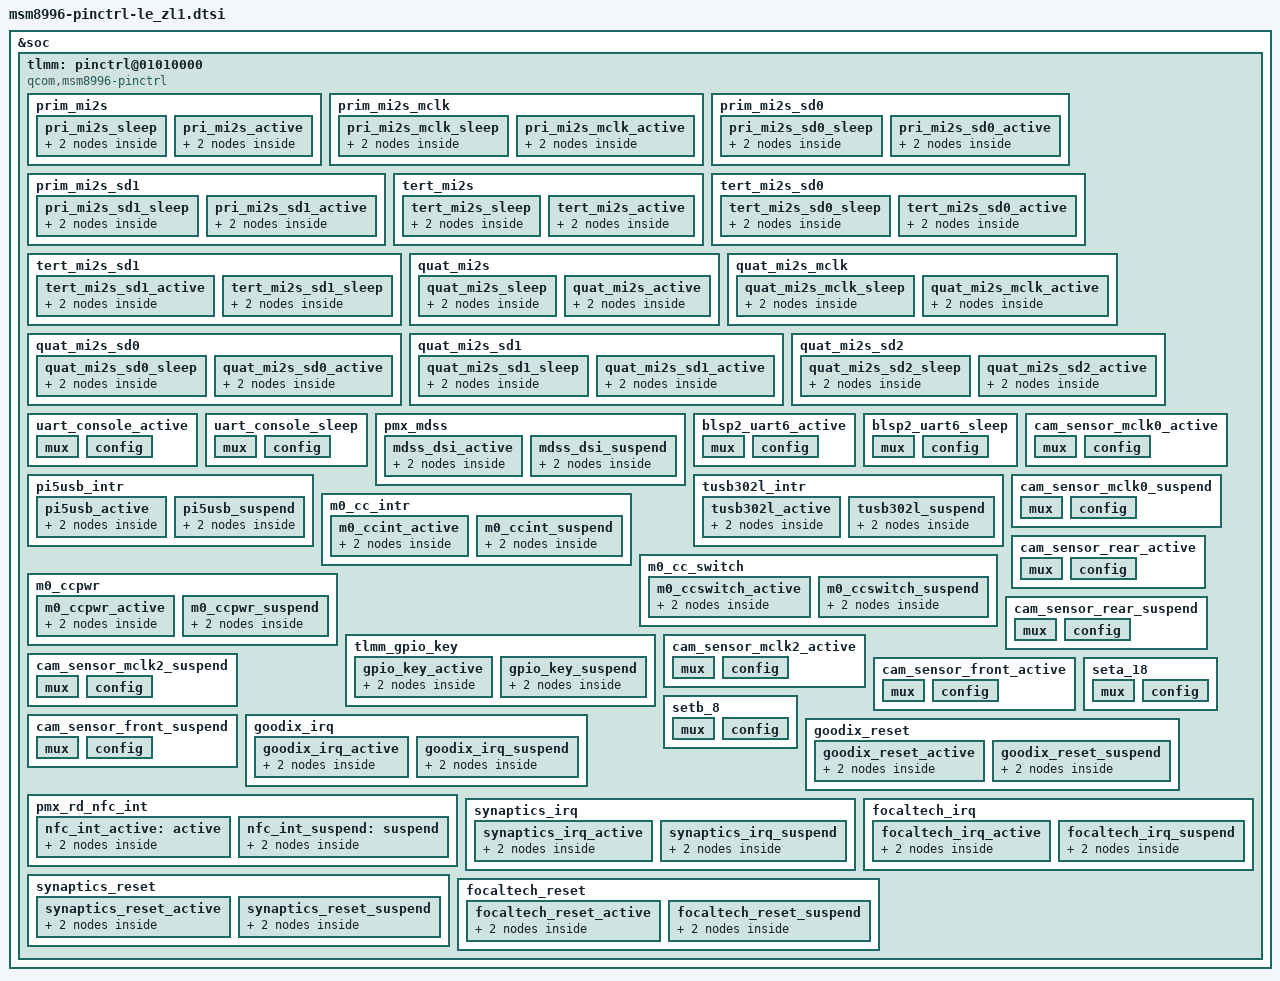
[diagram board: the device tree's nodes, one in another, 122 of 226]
/* Copyright (c) 2014-2015, The Linux Foundation. All rights reserved.
 *
 * This program is free software; you can redistribute it and/or modify
 * it under the terms of the GNU General Public License version 2 and
 * only version 2 as published by the Free Software Foundation.
 *
 * This program is distributed in the hope that it will be useful,
 * but WITHOUT ANY WARRANTY; without even the implied warranty of
 * MERCHANTABILITY or FITNESS FOR A PARTICULAR PURPOSE.  See the
 * GNU General Public License for more details.
 */

&soc {
	tlmm: pinctrl@01010000 {
		compatible = "qcom,msm8996-pinctrl";
		reg = <0x01010000 0x300000>;
		interrupts = <0 208 0>;
		gpio-controller;
		#gpio-cells = <2>;
		interrupt-controller;
		#interrupt-cells = <2>;

/*********** audio MI2S gpio config start ***********/
		prim_mi2s {
			pri_mi2s_sleep: pri_mi2s_sleep {
				mux {
					pins = "gpio65", "gpio66";
					function = "pri_mi2s";
				};
				config {
					pins = "gpio65", "gpio66";
					drive-strength = <2>;   /* 2 mA */
					bias-pull-down;         /* PULL DOWN */
				};
			};
			pri_mi2s_active: pri_mi2s_active {
				mux {
					pins = "gpio65", "gpio66";
					function = "pri_mi2s";
				};
				config {
					pins = "gpio65", "gpio66";
					drive-strength = <8>;   /* 8 mA */
					bias-disable;           /* NO PULL */
					output-high;
				};
			};
		};

		prim_mi2s_mclk {
			pri_mi2s_mclk_sleep: pri_mi2s_mclk_sleep {
				mux {
					pins = "gpio64";
					function = "pri_mi2s";
				};
				config {
					pins = "gpio64";
					drive-strength = <2>;   /* 2 mA */
					bias-pull-down;         /* PULL DOWN */
				};
			};
			pri_mi2s_mclk_active: pri_mi2s_mclk_active {
				mux {
					pins = "gpio64";
					function = "pri_mi2s";
				};
				config {
					pins = "gpio64";
					drive-strength = <8>;   /* 8 mA */
					bias-disable;           /* NO PULL */
					output-high;
				};
			};
		};

		prim_mi2s_sd0 {
			pri_mi2s_sd0_sleep: pri_mi2s_sd0_sleep {
				mux {
					pins = "gpio67";
					function = "pri_mi2s";
				};
				config {
					pins = "gpio67";
					drive-strength = <2>;   /* 2 mA */
					bias-pull-down;         /* PULL DOWN */
				};
			};
			pri_mi2s_sd0_active: pri_mi2s_sd0_active {
				mux {
					pins = "gpio67";
					function = "pri_mi2s";
				};
				config {
					pins = "gpio67";
					drive-strength = <8>;   /* 8 mA */
					bias-disable;           /* NO PULL */
				};
			};
		};

		prim_mi2s_sd1 {
			pri_mi2s_sd1_sleep: pri_mi2s_sd1_sleep {
				mux {
					pins = "gpio68";
					function = "pri_mi2s";
				};
				config {
					pins = "gpio68";
					drive-strength = <2>;   /* 2 mA */
					bias-pull-down;         /* PULL DOWN */
				};
			};
			pri_mi2s_sd1_active: pri_mi2s_sd1_active {
				mux {
					pins = "gpio68";
					function = "pri_mi2s";
				};
				config {
					pins = "gpio68";
					drive-strength = <8>;   /* 8 mA */
					bias-disable;           /* NO PULL */
				};
			};
		};

		tert_mi2s {
			tert_mi2s_sleep: tert_mi2s_sleep {
				mux {
					pins = "gpio75", "gpio76";
					function = "ter_mi2s";
				};

				config {
					pins = "gpio75", "gpio76";
					drive-strength = <2>;   /* 2 mA */
					bias-pull-down;         /* PULL DOWN */
				};
			};
			tert_mi2s_active: tert_mi2s_active {
				mux {
					pins = "gpio75", "gpio76";
					function = "ter_mi2s";
				};

				config {
					pins = "gpio75", "gpio76";
					drive-strength = <8>;   /* 8 mA */
					bias-disable;           /* NO PULL */
					output-high;
				};
			};
		};

		tert_mi2s_sd0 {
			tert_mi2s_sd0_sleep: tert_mi2s_sd0_sleep {
				mux {
					pins = "gpio77";
					function = "ter_mi2s";
				};

				config {
					pins = "gpio77";
					drive-strength = <2>;   /* 2 mA */
					bias-pull-down;         /* PULL DOWN */
				};
			};
			tert_mi2s_sd0_active: tert_mi2s_sd0_active {
				mux {
					pins = "gpio77";
					function = "ter_mi2s";
				};

				config {
					pins = "gpio77";
					drive-strength = <8>;   /* 8 mA */
					bias-disable;           /* NO PULL */
				};
			};
		};

		tert_mi2s_sd1 {
			tert_mi2s_sd1_active: tert_mi2s_sd1_active {
				mux {
					pins = "gpio78";
					function = "ter_mi2s";
				};

				config {
					pins = "gpio78";
					drive-strength = <8>;   /* 8 mA */
					bias-disable;           /* NO PULL */
				};
			};

			tert_mi2s_sd1_sleep: tert_mi2s_sd1_sleep {
				mux {
					pins = "gpio78";
					function = "ter_mi2s";
				};

				config {
					pins = "gpio78";
					drive-strength = <2>;   /* 2 mA */
					bias-pull-down;         /* PULL DOWN */
				};
			};
		};

		quat_mi2s {
			quat_mi2s_sleep: quat_mi2s_sleep {
				mux {
					pins = "gpio58", "gpio59";
					function = "qua_mi2s";
				};

				config {
					pins = "gpio58", "gpio59";
					drive-strength = <2>;   /* 2 mA */
					bias-pull-down;         /* PULL DOWN */
				};
			};
			quat_mi2s_active: quat_mi2s_active {
				mux {
					pins = "gpio58", "gpio59";
					function = "qua_mi2s";
				};

				config {
					pins = "gpio58", "gpio59";
					drive-strength = <8>;   /* 8 mA */
					bias-disable;           /* NO PULL */
					output-high;
				};
			};
		};

		quat_mi2s_mclk {
			quat_mi2s_mclk_sleep: quat_mi2s_mclk_sleep {
				mux {
					pins = "gpio57";
					function = "qua_mi2s";
				};
				config {
					pins = "gpio57";
					drive-strength = <2>;   /* 2 mA */
					bias-pull-down;         /* PULL DOWN */
				};
			};
			quat_mi2s_mclk_active: quat_mi2s_mclk_active {
				mux {
					pins = "gpio57";
					function = "qua_mi2s";
				};
				config {
					pins = "gpio57";
					drive-strength = <8>;   /* 8 mA */
					bias-disable;           /* NO PULL */
					output-high;
				};
			};
		};

		quat_mi2s_sd0 {
			quat_mi2s_sd0_sleep: quat_mi2s_sd0_sleep {
				mux {
					pins = "gpio60";
					function = "qua_mi2s";
				};

				config {
					pins = "gpio60";
					drive-strength = <2>;   /* 2 mA */
					bias-pull-down;         /* PULL DOWN */
				};
			};
			quat_mi2s_sd0_active: quat_mi2s_sd0_active {
				mux {
					pins = "gpio60";
					function = "qua_mi2s";
				};

				config {
					pins = "gpio60";
					drive-strength = <8>;   /* 8 mA */
					bias-disable;           /* NO PULL */
				};
			};
		};

		quat_mi2s_sd1 {
			quat_mi2s_sd1_sleep: quat_mi2s_sd1_sleep {
				mux {
					pins = "gpio61";
					function = "qua_mi2s";
				};
				config {
					pins = "gpio61";
					drive-strength = <2>;   /* 2 mA */
					bias-pull-down;         /* PULL DOWN */
				};
			};
			quat_mi2s_sd1_active: quat_mi2s_sd1_active {
				mux {
					pins = "gpio61";
					function = "qua_mi2s";
				};
				config {
					pins = "gpio61";
					function = "qua_mi2s";
					drive-strength = <8>;   /* 8 mA */
					bias-disable;           /* NO PULL */
				};
			};
		};

		quat_mi2s_sd2 {
			quat_mi2s_sd2_sleep: quat_mi2s_sd2_sleep {
				mux {
					pins = "gpio62";
					function = "qua_mi2s";
				};
				config {
					pins = "gpio62";
					drive-strength = <2>;   /* 2 mA */
					bias-pull-down;         /* PULL DOWN */
				};
			};
			quat_mi2s_sd2_active: quat_mi2s_sd2_active {
				mux {
					pins = "gpio62";
					function = "qua_mi2s";
				};
				config {
					pins = "gpio62";
					drive-strength = <8>;   /* 8 mA */
					bias-disable;           /* NO PULL */
				};
			};
		};
/*********** audio MI2S gpio config end ***********/

/*********** UART gpio config start ***********/
		uart_console_active: uart_console_active {
			mux {
				pins = "gpio4", "gpio5";
				function = "blsp_uart8";
			};

			config {
				pins = "gpio4", "gpio5";
				drive-strength = <6>;
				bias-disable;
			};
		};

		uart_console_sleep: uart_console_sleep {
			mux {
				pins = "gpio4", "gpio5";
				function = "gpio";
			};

			config {
				pins = "gpio4", "gpio5";
				drive-strength = <6>;
				bias-pull-down;
				output-low;
			};
		};
/*********** UART gpio config end ***********/

/*********** lcd gpio config start ***********/
		pmx_mdss: pmx_mdss {
			mdss_dsi_active: mdss_dsi_active {
				mux {
					pins = "gpio24";
					function = "gpio";
				};

				pmx_mdss {
					pins = "gpio24";
					drive-strength = <8>; /* 8 mA */
					bias-disable = <0>; /* no pull */
					output-high;
				};
			};
			mdss_dsi_suspend: mdss_dsi_suspend {
				mux {
					pins = "gpio24";
					function = "gpio";
				};

				config {
					pins = "gpio24";
					drive-strength = <2>; /* 2 mA */
					bias-pull-down;	/* pull	down */
				};
			};
		};
/*********** lcd gpio config end ***********/

/*********** IR MAXQ616 config start ***********/
	blsp2_uart6_active: blsp2_uart6_active {
		mux {
			pins = "gpio85", "gpio86";
			function = "blsp_uart12";
		};

		config {
			pins = "gpio85", "gpio86";
			drive-strength = <2>;
			bias-disable = <0>;
		};
	};

	blsp2_uart6_sleep: blsp2_uart6_sleep {
		mux {
			pins = "gpio85", "gpio86";
			function = "gpio";
		};

		config {
			pins = "gpio85", "gpio86";
			drive-strength = <2>;
			bias_disable = <0>;
			output-low;
		};
	};
/*********** IR MAXQ616 config end ***********/

/*********** usb cc logic gpio config start ***********/
		pi5usb_intr {
			pi5usb_active: pi5usb_active {
				mux {
					pins = "gpio73";
					function = "gpio";
				};

				config {
					pins = "gpio73";
					drive-strength = <2>;
					 bias-pull-up;
				};
			};
			pi5usb_suspend: pi5usb_suspend {
				mux {
					pins = "gpio73";
					function = "gpio";
				};

				config {
					pins = "gpio73";
					drive-strength = <2>;
					 bias-pull-up;
				};
			};
		};

		tusb302l_intr {
			tusb302l_active: tusb302l_active {
				mux {
					pins = "gpio73";
					function = "gpio";
				};

				config {
					pins = "gpio73";
					drive-strength = <2>;
					bias-pull-up;
				};
			};
			tusb302l_suspend: tusb302l_suspend {
				mux {
					pins = "gpio73";
					function = "gpio";
				};

				config {
					pins = "gpio73";
					drive-strength = <2>;
					bias-pull-up;
				};
			};
		};

		m0_cc_intr {
			m0_ccint_active: m0_ccint_active {
				mux {
					pins = "gpio73";
					function = "gpio";
				};

				config {
					pins = "gpio73";
					drive-strength = <2>;
					bias-pull-up;
				};
			};
			m0_ccint_suspend: m0_ccint_suspend {
				mux {
					pins = "gpio73";
					function = "gpio";
				};

				config {
					pins = "gpio73";
					drive-strength = <2>;
					bias-pull-up;
				};
			};
		};

		m0_cc_switch {
			m0_ccswitch_active: m0_ccswitch_active {
				mux {
					pins = "gpio58", "gpio59";
					function = "gpio";
				};

				config {
					pins = "gpio58", "gpio59";
					drive-strength = <2>;
					bias-pull-down;
				};
			};
			m0_ccswitch_suspend: m0_ccswitch_suspend {
				mux {
					pins = "gpio58", "gpio59";
					function = "gpio";
				};

				config {
					pins = "gpio58", "gpio59";
					drive-strength = <2>;
					bias-pull-down;
				};
			};
		};

		m0_ccpwr {
			m0_ccpwr_active: m0_ccpwr_active {
				mux {
					pins = "gpio60", "gpio61";
					function = "gpio";
				};

				config {
					pins = "gpio60", "gpio61";
					drive-strength = <2>;
					bias-pull-down;
				};
			};
			m0_ccpwr_suspend: m0_ccpwr_suspend {
				mux {
					pins = "gpio60", "gpio61";
					function = "gpio";
				};

				config {
					pins = "gpio60", "gpio61";
					drive-strength = <2>;
					bias-pull-down;
				};
			};
		};
/*********** usb cc logic gpio config end ***********/

/*********** touch key gpio config start ***********/
		tlmm_gpio_key{
			gpio_key_active: gpio_key_active {
				mux {
					pins = "gpio126";
					function = "gpio";
				};
				config {
					pins = "gpio126";
					drive-strength = <2>;
					bias-pull-up;
				};
			};
			gpio_key_suspend: gpio_key_suspend {
				mux {
					pins = "gpio126";
					function = "gpio";
				};
				config {
					pins = "gpio126";
					drive-strength = <2>;
					bias-pull-up;
				};
			};
		};
/*********** touch key gpio config end ***********/

/*********** Rear/Front Camera config start ***********/
		cam_sensor_mclk0_active: cam_sensor_mclk0_active {
			/* MCLK0 */
			mux {
				/* CLK, DATA */
				pins = "gpio13";
				function = "cam_mclk";
			};

			config {
				pins = "gpio13";
				bias-disable; /* No PULL */
				drive-strength = <2>; /* 2 MA */
			};
		};

		cam_sensor_mclk0_suspend: cam_sensor_mclk0_suspend {
			/* MCLK0 */
			mux {
				/* CLK, DATA */
				pins = "gpio13";
				function = "cam_mclk";
			};

			config {
				pins = "gpio13";
				bias-pull-down; /* PULL DOWN */
				drive-strength = <2>; /* 2 MA */
			};
		};

		cam_sensor_rear_active: cam_sensor_rear_active {
			/* RESET */
			mux {
				pins = "gpio29";
				function = "gpio";
			};

			config {
				pins = "gpio29";
				bias-disable; /* No PULL */
				drive-strength = <2>; /* 2 MA */
			};
		};

		cam_sensor_rear_suspend: cam_sensor_rear_suspend{
			/* RESET */
			mux {
				pins = "gpio29";
				function = "gpio";
			};

			config {
				pins = "gpio29";
				bias-disable; /* No PULL */
				drive-strength = <2>; /* 2 MA */
			};
		};

		cam_sensor_mclk2_active: cam_sensor_mclk2_active {
			/* MCLK1 */
			mux {
				/* CLK, DATA */
				pins = "gpio15";
				function = "cam_mclk";
			};

			config {
				pins = "gpio15";
				bias-disable; /* No PULL */
				drive-strength = <2>; /* 2 MA */
			};
		};

		cam_sensor_mclk2_suspend: cam_sensor_mclk2_suspend{
			/* MCLK1 */
			mux {
				/* CLK, DATA */
				pins = "gpio15";
				function = "cam_mclk";
			};

			config {
				pins = "gpio15";
				bias-pull-down; /* PULL DOWN */
				drive-strength = <2>; /* 2 MA */
			};
		};

		cam_sensor_front_active: cam_sensor_front_active{
			/* RESET */
			mux {
				pins = "gpio23";
				function = "gpio";
			};

			config {
				pins = "gpio23";
				bias-disable; /* No PULL */
				drive-strength = <2>; /* 2 MA */
			};
		};

		cam_sensor_front_suspend: cam_sensor_front_suspend{
			/* RESET */
			mux {
				pins = "gpio23";
				function = "gpio";
			};

			config {
				pins = "gpio23";
				bias-disable; /* No PULL */
				drive-strength = <2>; /* 2 MA */
			};
		};
/*********** Rear/Front Camera config end ***********/

/*********** smartpa 98927 config start ***********/
		seta_18: seta_18 {
			mux {
				pins = "gpio90";
				function = "gpio";
			};

			config {
				pins = "gpio90";
				drive-strength = <2>;
				bias-pull-up;         /* PULL UP */
			};
		};
/*********** smartpa 98927 config end ***********/

/*********** mic gnd switch config start ***********/
        setb_8: setb_8 {
            mux {
                pins = "gpio21";
                function = "gpio";
            };

            config {
                pins = "gpio21";
                drive-strength = <16>;
                bias-disable;
            };
        };
/*********** mic gnd switch config end ***********/

/****************goodix_irq reset + irq*********/
		goodix_irq{
			goodix_irq_active: goodix_irq_active{
				mux {
					pins = "gpio121";
					function = "gpio";
				};

				config {
					pins = "gpio121";
					bias-pull-down; /* PULL DOWN */
					drive-strength = <2>; /* 2 MA */
//					input-low;
				};
			};

			goodix_irq_suspend: goodix_irq_suspend{
				mux {
					pins = "gpio121";
					function = "gpio";
				};

				config {
					pins = "gpio121";
					bias-disable; /* No PULL */
//					bias-pull-up;
					drive-strength = <2>; /* 2 MA */
//					input-high;
				};
			};
		};


		goodix_reset{
			goodix_reset_active: goodix_reset_active{
				mux {
					pins = "gpio31";
					function = "gpio";
				};
				config {
					pins = "gpio31";
					bias-pull-down;
					drive-strength = <8>; /* 2 MA */
					output-low;
				};
			};
			goodix_reset_suspend: goodix_reset_suspend{
				mux {
					pins = "gpio31";
					function = "gpio";
				};
				config {
					pins = "gpio31";
					bias-disable; /* NO PULL  */
//					bias-pull-down;
					drive-strength = <2>; /* 2 MA */
					output-high;
				};
			};
		};
/****************goodix_irq reset + irq*********/
/******************nfc irq pinctrl begain*************/
		pmx_rd_nfc_int {
			nfc_int_active: active {
				mux {
					pins = "gpio95";
					function = "gpio";
				};

				config {
					pins = "gpio95";
					drive-strength = <6>;
					bias-pull-up;
				};
			};

			nfc_int_suspend: suspend {
				mux {
					pins = "gpio95";
					function = "gpio";
				};

				config {
					pins = "gpio95";
					drive-strength = <6>;
					bias-pull-up;
				};
			};
		};
/******************nfc irq pinctrl end*************/

/****************synaptics_irq reset + irq*********/
            synaptics_irq{
                synaptics_irq_active: synaptics_irq_active{
                    mux {
                        pins = "gpio125";
                        function = "gpio";
                    };

                    config {
                        pins = "gpio125";
                        bias-pull-up; /* PULL UP */
                        drive-strength = <16>; /* 16 MA */
    //                  input-low;
                    };
                };

                synaptics_irq_suspend: synaptics_irq_suspend{
                    mux {
                        pins = "gpio125";
                        function = "gpio";
                    };

                    config {
                        pins = "gpio125";
                        bias-disable; /* No PULL */
    //                  bias-pull-down;
                        drive-strength = <2>; /* 2 MA */
    //                  input-high;
                    };
                };
            };

            synaptics_reset{
                synaptics_reset_active: synaptics_reset_active{
                    mux {
                        pins = "gpio89";
                        function = "gpio";
                    };
                    config {
                        pins = "gpio89";
                        bias-pull-up;
                        drive-strength = <16>; /* 16 MA */
                        output-low;
                    };
                };
                synaptics_reset_suspend: synaptics_reset_suspend{
                    mux {
                        pins = "gpio89";
                        function = "gpio";
                    };
                    config {
                        pins = "gpio89";
                        bias-disable; /* NO PULL  */
    //                  bias-pull-down;
                        drive-strength = <2>; /* 2 MA */
                        output-high;
                    };
                };
            };
    /****************synaptics_irq reset + irq*********/

	/****************focaltech reset + irq*********/
		focaltech_irq{
			focaltech_irq_active: focaltech_irq_active{
				mux {
					pins = "gpio125";
					function = "gpio";
				};

				config {
					pins = "gpio125";
					bias-pull-up; /* PULL UP */
					drive-strength = <16>; /* 16 MA */
				};
			};

			focaltech_irq_suspend: focaltech_irq_suspend{
				mux {
					pins = "gpio125";
					function = "gpio";
				};

				config {
					pins = "gpio125";
					bias-disable; /* No PULL */
					drive-strength = <2>; /* 2 MA */
				};
			};
		};

		focaltech_reset{
			focaltech_reset_active: focaltech_reset_active{
				mux {
					pins = "gpio89";
					function = "gpio";
				};
				config {
					pins = "gpio89";
					bias-pull-up;
					drive-strength = <16>; /* 16 MA */
					output-high;
				};
			};
			focaltech_reset_suspend: focaltech_reset_suspend{
				mux {
					pins = "gpio89";
					function = "gpio";
				};
				config {
					pins = "gpio89";
					bias-disable; /* NO PULL  */
					drive-strength = <2>; /* 2 MA */
				};
			};
		};
	/****************focaltech reset + irq*********/

	};
};
